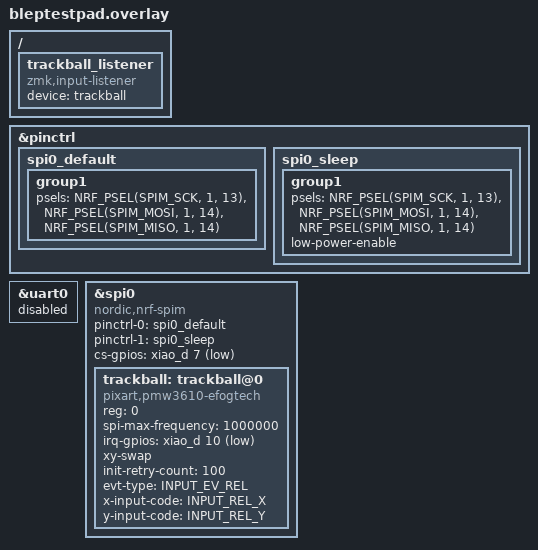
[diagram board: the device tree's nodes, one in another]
/*
 * Copyright (c) 2024 The ZMK Contributors
 *
 * SPDX-License-Identifier: MIT
 */

#include <dt-bindings/zmk/matrix_transform.h>
#include <zephyr/dt-bindings/input/input-event-codes.h>
//#include "adept-layout.dtsi"



&pinctrl {
    spi0_default: spi0_default {

        group1 {
            psels = <NRF_PSEL(SPIM_SCK, 1, 13)>,
                    <NRF_PSEL(SPIM_MOSI, 1, 14)>,
                    <NRF_PSEL(SPIM_MISO, 1, 14)>;
        };
    };

    spi0_sleep: spi0_sleep {
        group1 {
            psels = <NRF_PSEL(SPIM_SCK, 1, 13)>,
                    <NRF_PSEL(SPIM_MOSI, 1, 14)>,
                    <NRF_PSEL(SPIM_MISO, 1, 14)>;
            low-power-enable;
        };
    };
};

&uart0 {
    status = "disabled";
};

&spi0 {
    status = "okay";
    compatible = "nordic,nrf-spim";
    pinctrl-0 = <&spi0_default>;
    pinctrl-1 = <&spi0_sleep>;
    pinctrl-names = "default", "sleep";
    cs-gpios = <&xiao_d 7 GPIO_ACTIVE_LOW>;

    trackball: trackball@0 {
        status = "okay";
        compatible = "pixart,pmw3610-efogtech";
        reg = <0>;
        spi-max-frequency = <1000000>;
        irq-gpios = <&xiao_d 10 (GPIO_ACTIVE_LOW | GPIO_PULL_UP)>;
        xy-swap;
        init-retry-count = <100>;
        evt-type = <INPUT_EV_REL>;
        x-input-code = <INPUT_REL_X>;
        y-input-code = <INPUT_REL_Y>;
    };
};

/ {
  trackball_listener: trackball_listener {
    compatible = "zmk,input-listener";
    device = <&trackball>;
  };
}; 
